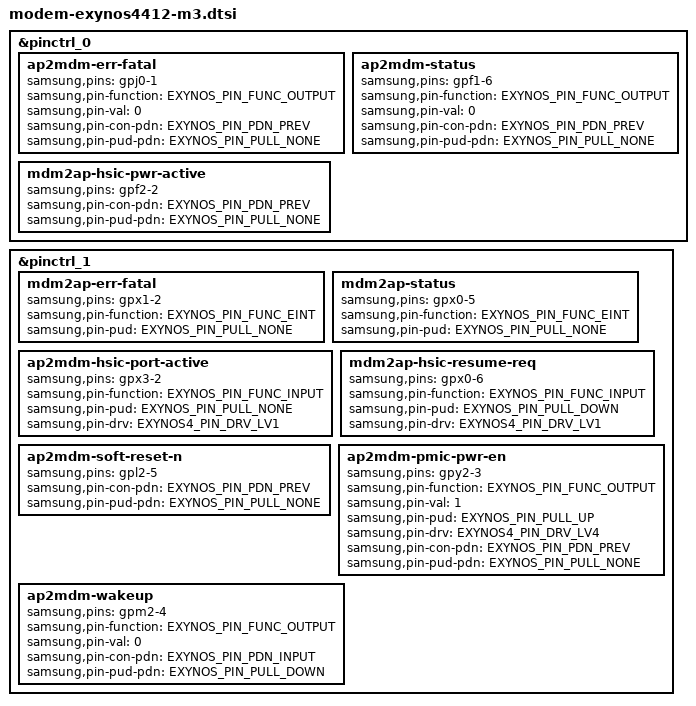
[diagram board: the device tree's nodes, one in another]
// SPDX-License-Identifier: GPL-2.0

#include <dt-bindings/pinctrl/samsung.h>

&pinctrl_0 {
	ap2mdm-err-fatal {
		samsung,pins = "gpj0-1";
		samsung,pin-function = <EXYNOS_PIN_FUNC_OUTPUT>;
		samsung,pin-val = <0>;
		samsung,pin-con-pdn = <EXYNOS_PIN_PDN_PREV>;
		samsung,pin-pud-pdn = <EXYNOS_PIN_PULL_NONE>;
	};
	ap2mdm-status {
		samsung,pins = "gpf1-6";
		samsung,pin-function = <EXYNOS_PIN_FUNC_OUTPUT>;
		samsung,pin-val = <0>;
		samsung,pin-con-pdn = <EXYNOS_PIN_PDN_PREV>;
		samsung,pin-pud-pdn = <EXYNOS_PIN_PULL_NONE>;
	};
	mdm2ap-hsic-pwr-active {
		samsung,pins = "gpf2-2";
		samsung,pin-con-pdn = <EXYNOS_PIN_PDN_PREV>;
		samsung,pin-pud-pdn = <EXYNOS_PIN_PULL_NONE>;
	};
};

&pinctrl_1 {
	mdm2ap-err-fatal {
		samsung,pins = "gpx1-2";
		samsung,pin-function = <EXYNOS_PIN_FUNC_EINT>;
		samsung,pin-pud = <EXYNOS_PIN_PULL_NONE>;
	};
	mdm2ap-status {
		samsung,pins = "gpx0-5";
		samsung,pin-function = <EXYNOS_PIN_FUNC_EINT>;
		samsung,pin-pud = <EXYNOS_PIN_PULL_NONE>;
	};
	ap2mdm-hsic-port-active {
		samsung,pins = "gpx3-2";
		samsung,pin-function = <EXYNOS_PIN_FUNC_INPUT>;
		samsung,pin-pud = <EXYNOS_PIN_PULL_NONE>;
		samsung,pin-drv = <EXYNOS4_PIN_DRV_LV1>;
	};
	mdm2ap-hsic-resume-req {
		samsung,pins = "gpx0-6";
		samsung,pin-function = <EXYNOS_PIN_FUNC_INPUT>;
		samsung,pin-pud = <EXYNOS_PIN_PULL_DOWN>;
		samsung,pin-drv = <EXYNOS4_PIN_DRV_LV1>;
	};
	ap2mdm-soft-reset-n {
		samsung,pins = "gpl2-5";
		samsung,pin-con-pdn = <EXYNOS_PIN_PDN_PREV>;
		samsung,pin-pud-pdn = <EXYNOS_PIN_PULL_NONE>;
	};
	ap2mdm-pmic-pwr-en {
		samsung,pins = "gpy2-3";
		samsung,pin-function = <EXYNOS_PIN_FUNC_OUTPUT>;
		samsung,pin-val = <1>;
		samsung,pin-pud = <EXYNOS_PIN_PULL_UP>;
		samsung,pin-drv = <EXYNOS4_PIN_DRV_LV4>;
		samsung,pin-con-pdn = <EXYNOS_PIN_PDN_PREV>;
		samsung,pin-pud-pdn = <EXYNOS_PIN_PULL_NONE>;
	};
	ap2mdm-wakeup {
		samsung,pins = "gpm2-4";
		samsung,pin-function = <EXYNOS_PIN_FUNC_OUTPUT>;
		samsung,pin-val = <0>;
		samsung,pin-con-pdn = <EXYNOS_PIN_PDN_INPUT>;
		samsung,pin-pud-pdn = <EXYNOS_PIN_PULL_DOWN>;
	};
};
